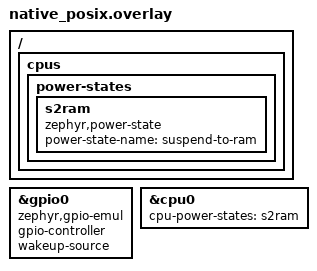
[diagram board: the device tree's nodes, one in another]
/*
 * Copyright (c) 2021 Intel Corporation.
 *
 * SPDX-License-Identifier: Apache-2.0
 */

&gpio0 {
	compatible = "zephyr,gpio-emul";
	gpio-controller;
	wakeup-source;
};

/ {
	cpus {
		power-states {
			s2ram: s2ram {
				compatible = "zephyr,power-state";
				power-state-name = "suspend-to-ram";
			};
		};
	};
};

&cpu0 {
	cpu-power-states = <&s2ram>;
};
